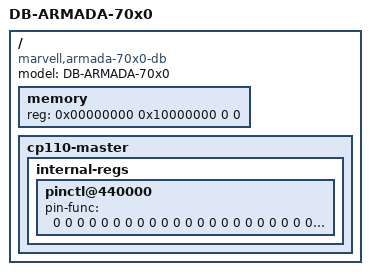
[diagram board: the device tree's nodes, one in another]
/*
 * ***************************************************************************
 * Copyright (C) 2015 Marvell International Ltd.
 * ***************************************************************************
 * This program is free software: you can redistribute it and/or modify it
 * under the terms of the GNU General Public License as published by the Free
 * Software Foundation, either version 2 of the License, or any later version.
 *
 * This program is distributed in the hope that it will be useful,
 * but WITHOUT ANY WARRANTY; without even the implied warranty of
 * MERCHANTABILITY or FITNESS FOR A PARTICULAR PURPOSE.  See the
 * GNU General Public License for more details.
 *
 * You should have received a copy of the GNU General Public License
 * along with this program.  If not, see <http://www.gnu.org/licenses/>.
 * ***************************************************************************
 */

/dts-v1/;

#include "armada-70x0.dtsi" /* include SoC device tree */

/ {
	model = "DB-ARMADA-70x0";
	compatible = "marvell,armada-70x0-db", "marvell,armada-70x0";

	memory {
		device_type = "memory";
		reg = <0x00000000 0x10000000 0 0>; /* 256 MB */
	};
	cp110-master {
		internal-regs {
			pinctl@440000 {
					/*   0 1 2 3 4 5 6 7 8 9 */
				pin-func = < 0 0 0 0 0 0 0 0 0 0
					     0 0 0 0 0 0 0 0 0 0
					     0 0 0 0 0 0 0 0 0 0
					     0 0 0 0 0 0 0 0 0 0
					     0 0 0 0 0 0 0 0 0 0
					     0 0 0 0 0 0 6 6 6 6
					     0 0 0 0>;
			};
		};
	};
};
